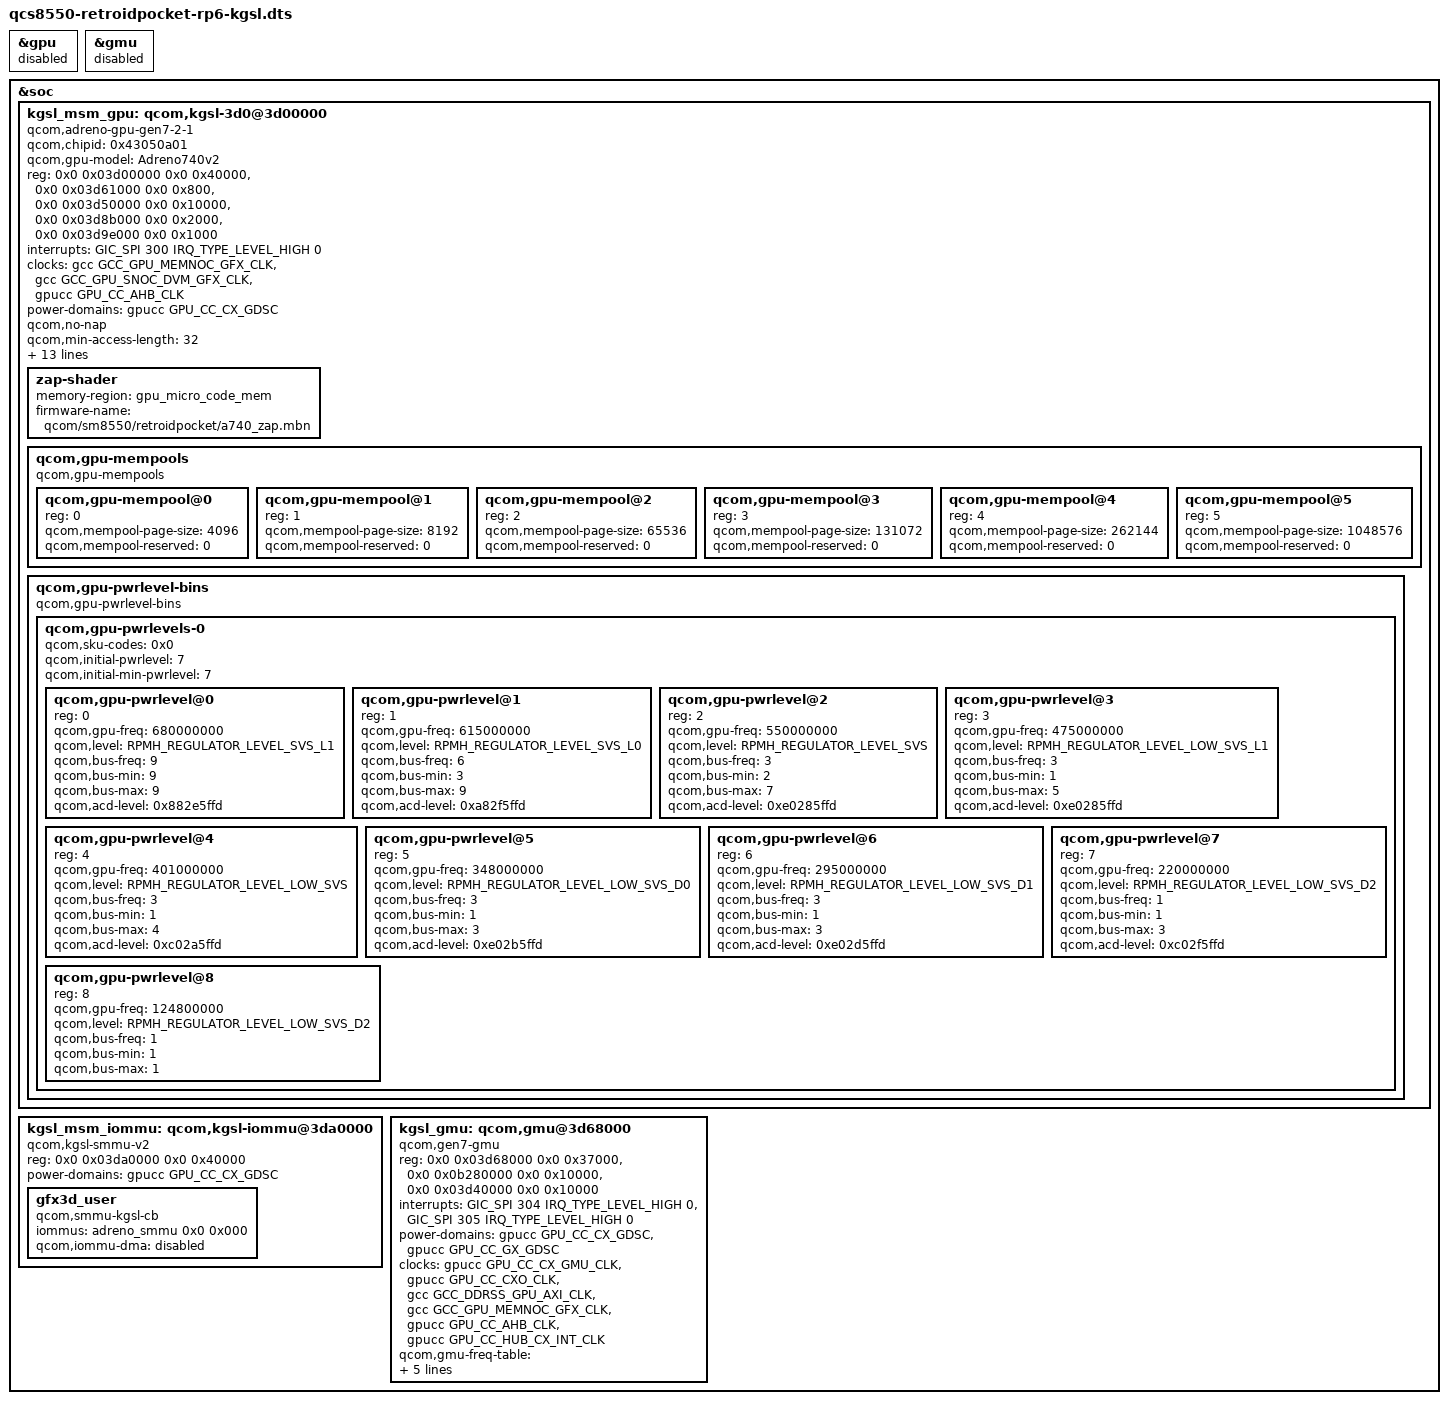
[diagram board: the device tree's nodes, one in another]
// SPDX-License-Identifier: GPL-2.0-only
/*
 * EXPERIMENTAL, UNTESTED: RP6 device tree with the GPU handed to Qualcomm's
 * KGSL driver (msm_kgsl.ko) instead of the mainline msm GPU driver. The msm
 * display (mdss/dpu) keeps running; only the gpu and gmu nodes are swapped.
 *
 * Adapted from the downstream kalama-gpu.dtsi and kalama-v2-gpu-pwrlevels.dtsi
 * (LineageOS android_kernel_qcom_sm8550-devicetrees, lineage-21) to mainline
 * labels: GDSCs are power domains, the SMMU is &adreno_smmu, and there is no
 * AOP mailbox (ACD stays off) and no coresight.
 */

#include "qcom/qcs8550-retroidpocket-rp6.dts"

#define MHZ_TO_KBPS(mhz, w) ((mhz * 1000000 * w) / (1024))

/* mainline msm must not touch the GPU any more */
&gpu {
	status = "disabled";
};

&gmu {
	status = "disabled";
};

&soc {
	kgsl_msm_gpu: qcom,kgsl-3d0@3d00000 {
		compatible = "qcom,adreno-gpu-gen7-2-1", "qcom,kgsl-3d0";
		/* downstream reads these from socinfo, which mainline does not export */
		qcom,chipid = <0x43050a01>;
		qcom,gpu-model = "Adreno740v2";
		reg = <0x0 0x03d00000 0x0 0x40000>, <0x0 0x03d61000 0x0 0x800>,
		      <0x0 0x03d50000 0x0 0x10000>, <0x0 0x03d8b000 0x0 0x2000>,
		      <0x0 0x03d9e000 0x0 0x1000>;
		reg-names = "kgsl_3d0_reg_memory", "cx_dbgc", "rscc",
			    "isense_cntl", "cx_misc";
		interrupts = <GIC_SPI 300 IRQ_TYPE_LEVEL_HIGH 0>;
		interrupt-names = "kgsl_3d0_irq";

		clocks = <&gcc GCC_GPU_MEMNOC_GFX_CLK>,
			 <&gcc GCC_GPU_SNOC_DVM_GFX_CLK>,
			 <&gpucc GPU_CC_AHB_CLK>;
		clock-names = "gcc_gpu_memnoc_gfx", "gcc_gpu_snoc_dvm_gfx",
			      "gpu_cc_ahb";

		power-domains = <&gpucc GPU_CC_CX_GDSC>;
		power-domain-names = "cx";

		qcom,no-nap;
		qcom,min-access-length = <32>;
		qcom,ubwc-mode = <4>;

		qcom,tzone-names = "gpuss-0", "gpuss-1", "gpuss-2", "gpuss-3",
				   "gpuss-4", "gpuss-5", "gpuss-6", "gpuss-7";

		interconnects = <&gem_noc MASTER_GFX3D QCOM_ICC_TAG_ALWAYS
				 &mc_virt SLAVE_EBI1 QCOM_ICC_TAG_ALWAYS>;
		interconnect-names = "gpu_icc_path";

		qcom,bus-table-cnoc = <0>, <100>;

		qcom,bus-table-ddr =
			<MHZ_TO_KBPS(0, 4)>,
			<MHZ_TO_KBPS(547, 4)>,
			<MHZ_TO_KBPS(768, 4)>,
			<MHZ_TO_KBPS(1555, 4)>,
			<MHZ_TO_KBPS(1708, 4)>,
			<MHZ_TO_KBPS(2092, 4)>,
			<MHZ_TO_KBPS(2736, 4)>,
			<MHZ_TO_KBPS(3187, 4)>,
			<MHZ_TO_KBPS(3686, 4)>,
			<MHZ_TO_KBPS(4224, 4)>;

		zap-shader {
			memory-region = <&gpu_micro_code_mem>;
			firmware-name = "qcom/sm8550/retroidpocket/a740_zap.mbn";
		};

		/*
		 * Page pools, same sizes as downstream but nothing pinned at boot:
		 * the downstream reservations hold about 100 MB that is never freed.
		 */
		qcom,gpu-mempools {
			#address-cells = <1>;
			#size-cells = <0>;
			compatible = "qcom,gpu-mempools";

			qcom,gpu-mempool@0 {
				reg = <0>;
				qcom,mempool-page-size = <4096>;
				qcom,mempool-reserved = <0>;
			};
			qcom,gpu-mempool@1 {
				reg = <1>;
				qcom,mempool-page-size = <8192>;
				qcom,mempool-reserved = <0>;
			};
			qcom,gpu-mempool@2 {
				reg = <2>;
				qcom,mempool-page-size = <65536>;
				qcom,mempool-reserved = <0>;
			};
			qcom,gpu-mempool@3 {
				reg = <3>;
				qcom,mempool-page-size = <131072>;
				qcom,mempool-reserved = <0>;
			};
			qcom,gpu-mempool@4 {
				reg = <4>;
				qcom,mempool-page-size = <262144>;
				qcom,mempool-reserved = <0>;
			};
			qcom,gpu-mempool@5 {
				reg = <5>;
				qcom,mempool-page-size = <1048576>;
				qcom,mempool-reserved = <0>;
			};
		};

		/*
		 * Power levels: the downstream bin for an unknown SKU (max 680 MHz).
		 * Mainline does not export the SoC feature code, so the 719 MHz bin
		 * is never selected.
		 */
		qcom,gpu-pwrlevel-bins {
			compatible = "qcom,gpu-pwrlevel-bins";
			#address-cells = <1>;
			#size-cells = <0>;

			qcom,gpu-pwrlevels-0 {

				#address-cells = <1>;
				#size-cells = <0>;

				qcom,sku-codes = <0x0>;

				qcom,initial-pwrlevel = <7>;
				qcom,initial-min-pwrlevel = <7>;

				qcom,gpu-pwrlevel@0 {
					reg = <0>;
					qcom,gpu-freq = <680000000>;
					qcom,level = <RPMH_REGULATOR_LEVEL_SVS_L1>;

					qcom,bus-freq = <9>;
					qcom,bus-min = <9>;
					qcom,bus-max = <9>;

					qcom,acd-level = <0x882e5ffd>;
				};
				qcom,gpu-pwrlevel@1 {
					reg = <1>;
					qcom,gpu-freq = <615000000>;
					qcom,level = <RPMH_REGULATOR_LEVEL_SVS_L0>;

					qcom,bus-freq = <6>;
					qcom,bus-min = <3>;
					qcom,bus-max = <9>;

					qcom,acd-level = <0xa82f5ffd>;
				};
				qcom,gpu-pwrlevel@2 {
					reg = <2>;
					qcom,gpu-freq = <550000000>;
					qcom,level = <RPMH_REGULATOR_LEVEL_SVS>;

					qcom,bus-freq = <3>;
					qcom,bus-min = <2>;
					qcom,bus-max = <7>;

					qcom,acd-level = <0xe0285ffd>;
				};
				qcom,gpu-pwrlevel@3 {
					reg = <3>;
					qcom,gpu-freq = <475000000>;
					qcom,level = <RPMH_REGULATOR_LEVEL_LOW_SVS_L1>;

					qcom,bus-freq = <3>;
					qcom,bus-min = <1>;
					qcom,bus-max = <5>;

					qcom,acd-level = <0xe0285ffd>;
				};
				qcom,gpu-pwrlevel@4 {
					reg = <4>;
					qcom,gpu-freq = <401000000>;
					qcom,level = <RPMH_REGULATOR_LEVEL_LOW_SVS>;

					qcom,bus-freq = <3>;
					qcom,bus-min = <1>;
					qcom,bus-max = <4>;

					qcom,acd-level = <0xc02a5ffd>;
				};
				qcom,gpu-pwrlevel@5 {
					reg = <5>;
					qcom,gpu-freq = <348000000>;
					qcom,level = <RPMH_REGULATOR_LEVEL_LOW_SVS_D0>;

					qcom,bus-freq = <3>;
					qcom,bus-min = <1>;
					qcom,bus-max = <3>;

					qcom,acd-level = <0xe02b5ffd>;
				};
				qcom,gpu-pwrlevel@6 {
					reg = <6>;
					qcom,gpu-freq = <295000000>;
					qcom,level = <RPMH_REGULATOR_LEVEL_LOW_SVS_D1>;

					qcom,bus-freq = <3>;
					qcom,bus-min = <1>;
					qcom,bus-max = <3>;

					qcom,acd-level = <0xe02d5ffd>;
				};
				qcom,gpu-pwrlevel@7 {
					reg = <7>;
					qcom,gpu-freq = <220000000>;
					qcom,level = <RPMH_REGULATOR_LEVEL_LOW_SVS_D2>;

					qcom,bus-freq = <1>;
					qcom,bus-min = <1>;
					qcom,bus-max = <3>;

					qcom,acd-level = <0xc02f5ffd>;
				};
				qcom,gpu-pwrlevel@8 {
					reg = <8>;
					qcom,gpu-freq = <124800000>;
					qcom,level = <RPMH_REGULATOR_LEVEL_LOW_SVS_D2>;

					qcom,bus-freq = <1>;
					qcom,bus-min = <1>;
					qcom,bus-max = <1>;
				};

			};
		};
	};

	kgsl_msm_iommu: qcom,kgsl-iommu@3da0000 {
		compatible = "qcom,kgsl-smmu-v2";
		reg = <0x0 0x03da0000 0x0 0x40000>;
		power-domains = <&gpucc GPU_CC_CX_GDSC>;
		power-domain-names = "cx";

		/*
		 * SID 0 makes mainline arm-smmu-qcom treat this as the GPU:
		 * context bank 0, TTBR1 split and adreno_smmu_priv callbacks.
		 * kernel/patches/0003 gives it an identity default domain so
		 * that only KGSL's own domain gets a context bank.
		 */
		gfx3d_user: gfx3d_user {
			compatible = "qcom,smmu-kgsl-cb";
			iommus = <&adreno_smmu 0x0 0x000>;
			qcom,iommu-dma = "disabled";
		};
	};

	kgsl_gmu: qcom,gmu@3d68000 {
		compatible = "qcom,gen7-gmu";
		reg = <0x0 0x03d68000 0x0 0x37000>,
		      <0x0 0x0b280000 0x0 0x10000>,
		      <0x0 0x03d40000 0x0 0x10000>;
		reg-names = "gmu", "gmu_pdc", "gmu_ao_blk_dec0";

		interrupts = <GIC_SPI 304 IRQ_TYPE_LEVEL_HIGH 0>,
			     <GIC_SPI 305 IRQ_TYPE_LEVEL_HIGH 0>;
		interrupt-names = "hfi", "gmu";

		power-domains = <&gpucc GPU_CC_CX_GDSC>,
				<&gpucc GPU_CC_GX_GDSC>;
		power-domain-names = "cx", "gx";

		clocks = <&gpucc GPU_CC_CX_GMU_CLK>,
			 <&gpucc GPU_CC_CXO_CLK>,
			 <&gcc GCC_DDRSS_GPU_AXI_CLK>,
			 <&gcc GCC_GPU_MEMNOC_GFX_CLK>,
			 <&gpucc GPU_CC_AHB_CLK>,
			 <&gpucc GPU_CC_HUB_CX_INT_CLK>;
		clock-names = "gmu_clk", "cxo_clk", "axi_clk",
			      "memnoc_clk", "ahb_clk", "hub_clk";

		qcom,gmu-freq-table = <220000000 RPMH_REGULATOR_LEVEL_LOW_SVS>,
				      <550000000 RPMH_REGULATOR_LEVEL_SVS>;

		iommus = <&adreno_smmu 0x5 0x000>;
		qcom,iommu-dma = "disabled";

		qcom,ipc-core = <0x00400000 0x100000>;
	};
};
